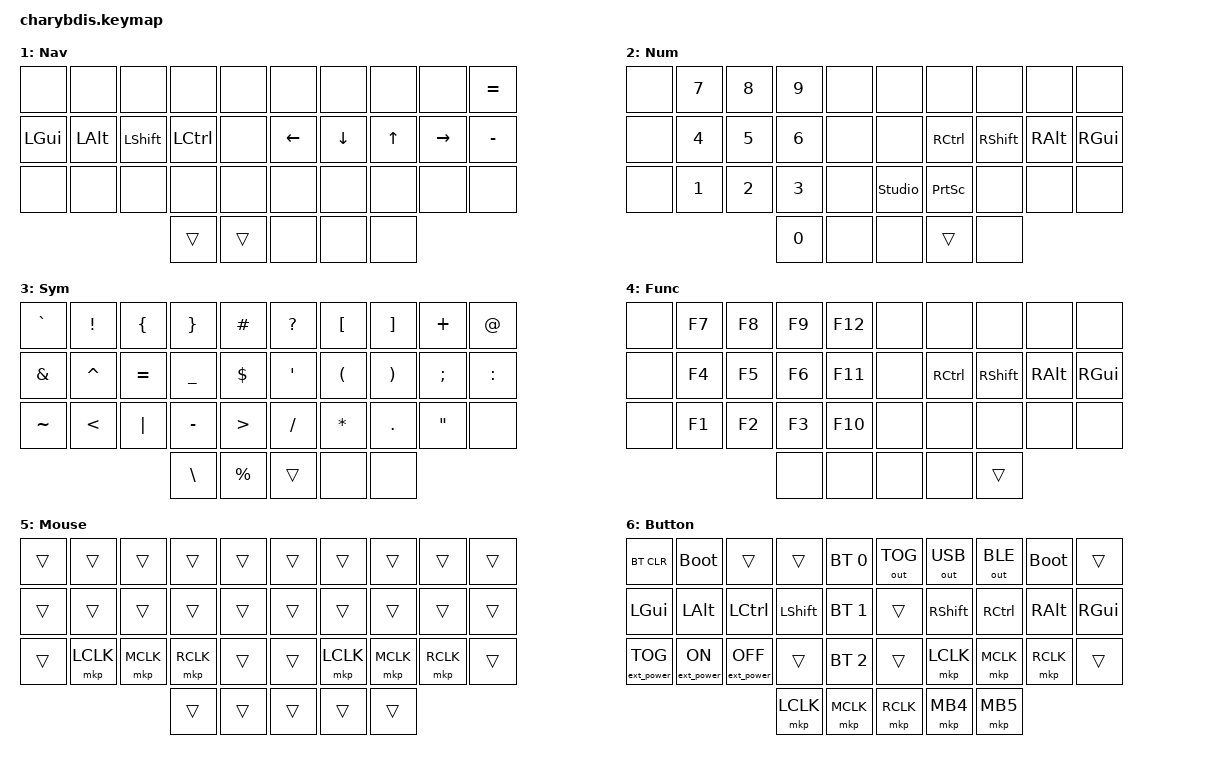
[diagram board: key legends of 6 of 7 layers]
#include <behaviors.dtsi>
#include <dt-bindings/zmk/keys.h>
#include <dt-bindings/zmk/bt.h>
#include <dt-bindings/zmk/ext_power.h>
#include <dt-bindings/zmk/mouse.h>
#include <dt-bindings/zmk/outputs.h>
#include <input/processors.dtsi>
#include <dt-bindings/zmk/input_transform.h>

#define Base 0
#define Nav 1
#define Num 2
#define Sym 3
#define Func 4
#define Mouse 5
#define Button 6

#define HRML(k1,k2,k3,k4) &hml LGUI k1 &hml LALT k2 &hml LSHFT k3 &hml LCTRL k4
#define HRMR(k1,k2,k3,k4) &hmr RCTRL k1 &hmr RSHFT k2 &hmr RALT k3 &hmr RGUI k4

/* Adjust if your shield's matrix transform orders thumb keys differently */
#define KEYS_L 0 1 2 3 4 10 11 12 13 14 20 21 22 23 24
#define KEYS_R 5 6 7 8 9 15 16 17 18 19 25 26 27 28 29
#define THUMBS 30 31 32 33 34

/ {
    trackball_listener {
        compatible = "zmk,input-listener";
        device = <&trackball_split>;

        snipe {
            layers = <Mouse>;
            input-processors = <&zip_xy_scaler 1 3>;
        };

        scroll {
            layers = <Nav>;
            input-processors = <&zip_xy_scaler 1 3>, <&zip_xy_to_scroll_mapper>, <&zip_scroll_transform (INPUT_TRANSFORM_Y_INVERT)>;
        };
    };

    behaviors {
        hml: home_row_mod_left {
            compatible = "zmk,behavior-hold-tap";
            #binding-cells = <2>;
            flavor = "balanced";
            tapping-term-ms = <280>;
            quick-tap-ms = <175>;
            require-prior-idle-ms = <150>;
            hold-trigger-key-positions = <KEYS_R THUMBS>;
            hold-trigger-on-release;
            bindings = <&kp>, <&kp>;
        };

        hmr: home_row_mod_right {
            compatible = "zmk,behavior-hold-tap";
            #binding-cells = <2>;
            flavor = "balanced";
            tapping-term-ms = <280>;
            quick-tap-ms = <175>;
            require-prior-idle-ms = <150>;
            hold-trigger-key-positions = <KEYS_L THUMBS>;
            hold-trigger-on-release;
            bindings = <&kp>, <&kp>;
        };

        lt: layer_tap {
            compatible = "zmk,behavior-hold-tap";
            #binding-cells = <2>;
            flavor = "balanced";
            tapping-term-ms = <240>;
            quick-tap-ms = <150>;
            bindings = <&mo>, <&kp>;
        };
    };

    chosen {
		zmk,matrix-transform = &five_column_transform;
    };

    keymap {
        compatible = "zmk,keymap";

        Base {
            display-name = "Base";
            bindings = <
                &kp B      &kp L      &kp D      &kp C      &kp V          &kp J      &kp F      &kp O      &kp U      &kp COMMA
                HRML(N, R, T, S)                              &kp G          &kp Y      HRMR(H, A, E, I)
                &kp X      &kp Q      &kp M      &kp W      &kp Z          &kp K      &kp P      &kp ESC    &kp ENTER  &lt Func DEL
                                                 &lt Nav SPACE &mt LSHFT TAB &mo Sym     &lt Num BSPC &mo Button
            >;
        };

        Nav {
            display-name = "Nav";
            bindings = <
                &none      &none      &none      &none      &none          &none      &none      &none      &none      &kp EQUAL
                &kp LGUI   &kp LALT   &kp LSHFT  &kp LCTRL  &none          &kp LEFT   &kp DOWN   &kp UP     &kp RIGHT  &kp MINUS
                &none      &none      &none      &none      &none          &none      &none      &none      &none      &none
                                                 &trans     &trans     &none          &none      &none
            >;
        };

        Num {
            display-name = "Num";
            bindings = <
                &none      &kp N7     &kp N8     &kp N9     &none          &none      &none      &none      &none      &none
                &none      &kp N4     &kp N5     &kp N6     &none          &none      &kp RCTRL  &kp RSHFT  &kp RALT   &kp RGUI
                &none      &kp N1     &kp N2     &kp N3     &none          &studio_unlock &kp PSCRN &none   &none      &none
                                                 &kp N0     &none      &none          &trans     &none
            >;
        };

        Sym {
            display-name = "Sym";
            bindings = <
                &kp GRAVE  &kp EXCL   &kp LBRC   &kp RBRC   &kp HASH       &kp QMARK  &kp LBKT   &kp RBKT   &kp PLUS   &kp AT
                &kp AMPS   &kp CARET  &kp EQUAL  &kp UNDER  &kp DLLR       &kp APOS   &kp LPAR   &kp RPAR   &kp SEMI   &kp COLON
                &kp TILDE  &kp LT     &kp PIPE   &kp MINUS  &kp GT         &kp FSLH   &kp STAR   &kp DOT    &kp DQT    &none
                                                 &kp BSLH   &kp PRCNT  &trans         &none      &none
            >;
        };

        Func {
            display-name = "Func";
            bindings = <
                &none      &kp F7     &kp F8     &kp F9     &kp F12        &none      &none      &none      &none      &none
                &none      &kp F4     &kp F5     &kp F6     &kp F11        &none      &kp RCTRL  &kp RSHFT  &kp RALT   &kp RGUI
                &none      &kp F1     &kp F2     &kp F3     &kp F10        &none      &none      &none      &none      &none
                                                 &none      &none      &none          &none      &trans
            >;
        };

        Mouse {
            display-name = "Mouse";
            bindings = <
                &trans     &trans     &trans     &trans     &trans         &trans     &trans     &trans     &trans     &trans
                &trans     &trans     &trans     &trans     &trans         &trans     &trans     &trans     &trans     &trans
                &trans     &mkp LCLK  &mkp MCLK  &mkp RCLK  &trans         &trans     &mkp LCLK  &mkp MCLK  &mkp RCLK  &trans
                                                 &trans     &trans     &trans         &trans     &trans
            >;
        };

        Button {
            display-name = "Button";
            bindings = <
                &bt BT_CLR &bootloader &trans    &trans     &bt BT_SEL 0   &out OUT_TOG &out OUT_USB &out OUT_BLE &bootloader &trans
                &kp LGUI   &kp LALT   &kp LCTRL  &kp LSHFT  &bt BT_SEL 1   &trans     &kp RSHFT  &kp RCTRL  &kp RALT   &kp RGUI
                &ext_power EP_TOG &ext_power EP_ON &ext_power EP_OFF &trans &bt BT_SEL 2 &trans &mkp LCLK &mkp MCLK &mkp RCLK &trans
                                                 &mkp LCLK  &mkp MCLK  &mkp RCLK      &mkp MB4   &mkp MB5
            >;
        };
    };
};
